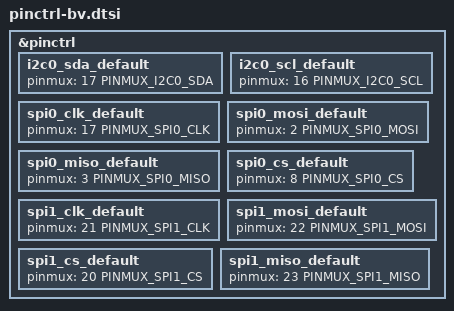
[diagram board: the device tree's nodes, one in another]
/*
 * Copyright (c) 2024-2026 Atmosic
 *
 * SPDX-License-Identifier: LicenseRef-Atmosic
 */

#include <atm34_pinmux.h>

&pinctrl {
	i2c0_sda_default: i2c0_sda_default {
		pinmux = <17 PINMUX_I2C0_SDA>;
	};

	i2c0_scl_default: i2c0_scl_default {
		pinmux = <16 PINMUX_I2C0_SCL>;
	};

	/* SPI0 */
	spi0_clk_default: spi0_clk_default {
		pinmux = <17 PINMUX_SPI0_CLK>;
	};

	spi0_mosi_default: spi0_mosi_default {
		pinmux = <2 PINMUX_SPI0_MOSI>;
	};

	spi0_miso_default: spi0_miso_default {
		pinmux = <3 PINMUX_SPI0_MISO>;
	};

	spi0_cs_default: spi0_cs_default {
		pinmux = <8 PINMUX_SPI0_CS>;
	};

	/* SPI1 */
	spi1_clk_default: spi1_clk_default {
		pinmux = <21 PINMUX_SPI1_CLK>;
	};

	spi1_mosi_default: spi1_mosi_default {
		pinmux = <22 PINMUX_SPI1_MOSI>;
	};

	spi1_cs_default: spi1_cs_default {
		pinmux = <20 PINMUX_SPI1_CS>;
	};

	spi1_miso_default: spi1_miso_default {
		pinmux = <23 PINMUX_SPI1_MISO>;
	};
};
